AUTOSAR XML (schema 00049)
package /SwComponentTypes
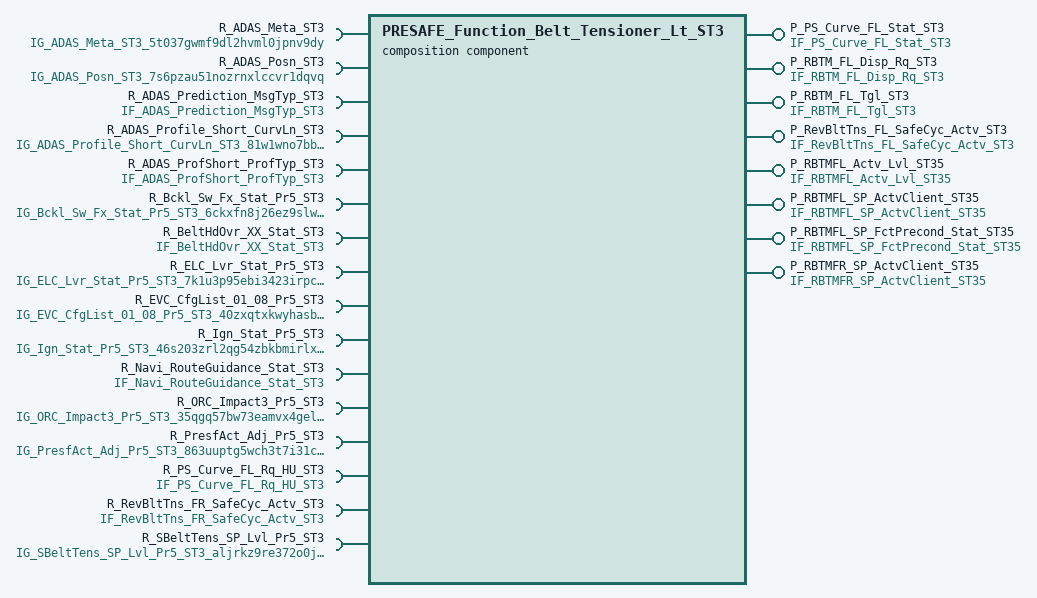
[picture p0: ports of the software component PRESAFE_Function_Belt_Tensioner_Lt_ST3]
  composition sw component type PRESAFE_Function_Belt_Tensioner_Lt_ST3  # Ausführung der reversiblen Gurtsraffung mit Hilfe des Gurtes in Gefahrensituationen / execution of a reversible belt tensioning by belt in critical situations
    4 x provide port:
      P_PS_Curve_FL_Stat_ST3: nonqueued-sender-com-spec{data-element=PS_Curve_FL_Stat_ST3, init-value=constant-reference=XDIS_avyye5ls1y4c08a0jv466vs3h}, provided-interface=IF_PS_Curve_FL_Stat_ST3  # PreSafe Curve Status vorne links / PreSafe Curve mode state front left
      P_RBTM_FL_Disp_Rq_ST3: nonqueued-sender-com-spec{data-element=RBTM_FL_Disp_Rq_ST3, init-value=constant-reference=XDIS_cy54nb3vm043oo6et4rw4sxxi}, provided-interface=IF_RBTM_FL_Disp_Rq_ST3  # Presafe Kombimeldung vorne links anzeigen / Presafe display request front left
      P_RBTM_FL_Tgl_ST3: nonqueued-sender-com-spec{data-element=RBTM_FL_Tgl_ST3, init-value=constant-reference=XDIS_h5tcyk98kzbgrc5svasomeyt}, provided-interface=IF_RBTM_FL_Tgl_ST3  # Presafe Togglebit
      P_RevBltTns_FL_SafeCyc_Actv_ST3: nonqueued-sender-com-spec{data-element=RevBltTns_FL_SafeCyc_Actv_ST3, init-value=constant-reference=XDIS_f4mtuwvd3r353o80f6rps7w7}, provided-interface=IF_RevBltTns_FL_SafeCyc_Actv_ST3  # Reversibler Gurtstraffer vorne links Sicherheits-Straffzyklus aktiv / Reversible belt tensioner front left safety tensioning cycle active
    15 x require port:
      R_ADAS_Meta_ST3: nonqueued-receiver-com-spec{data-element=ADAS_Meta_ST3, reception-props=timeout=10.1, alive-timeout=10.1, init-value=constant-reference=XDIS_e0ppmab9qlp72wzp0n595ikyr}, required-interface=IG_ADAS_Meta_ST3_5t037gwmf9dl2hvml0jpnv9dy  # ADAS Metadaten (degraded) / ADAS meta data (degraded)
      R_ADAS_Posn_ST3: nonqueued-receiver-com-spec{data-element=ADAS_Posn_ST3, reception-props=timeout=5.1, alive-timeout=5.1, init-value=constant-reference=XDIS_12iby7nm3kigcbaip97m7b94m}, required-interface=IG_ADAS_Posn_ST3_7s6pzau51nozrnxlccvr1dqvq  # ADAS Position (degraded)
      R_ADAS_Prediction_MsgTyp_ST3: nonqueued-receiver-com-spec{data-element=ADAS_Prediction_MsgTyp_ST3, reception-props=timeout=0, init-value=constant-reference=XDIS_2a2yz5m526fyufrfge0jdvur9}, required-interface=IF_ADAS_Prediction_MsgTyp_ST3  # ADAS Prediction: Message Type
      R_ADAS_Profile_Short_CurvLn_ST3: nonqueued-receiver-com-spec{data-element=ADAS_Profile_Short_CurvLn_ST3, reception-props=timeout=1.1, alive-timeout=1.1, init-value=constant-reference=XDIS_5q6kecggtt6ixzqit96uyqmo3}, required-interface=IG_ADAS_Profile_Short_CurvLn_ST3_81w1wno7bbxberhwp2jcfr8tz  # ADAS Kurzcharakteristik Curvature Linear (degraded) / ADAS short profile Curvature Linear (degraded)
      R_ADAS_ProfShort_ProfTyp_ST3: nonqueued-receiver-com-spec{data-element=ADAS_ProfShort_ProfTyp_ST3, reception-props=timeout=0, init-value=constant-reference=XDIS_5tr223jg6fys3d0tv4s093nze}, required-interface=IF_ADAS_ProfShort_ProfTyp_ST3  # Profile Short Message: Profiltyp / Profile Short Message: Profile Type
      R_Bckl_Sw_Fx_Stat_Pr5_ST3: nonqueued-receiver-com-spec{data-element=Bckl_Sw_Fx_Stat_Pr5_ST3, reception-props=timeout=0, end-to-end-transformation-com-spec-props{disable-end-to-end-check=false, max-delta-counter=10, max-error-state-init=7, max-error-state-invalid=7, max-error-state-valid=9, min-ok-state-init=3, min-ok-state-invalid=3, min-ok-state-valid=1, window-size-init=10, window-size-invalid=10, window-size-valid=10}, init-value=constant-reference=XDIS_by5k2ulzqy4hav7734lki195k}, required-interface=IG_Bckl_Sw_Fx_Stat_Pr5_ST3_6ckxfn8j26ez9slws8s7zuact  # Bckl Sw Fx Status ST3 (degraded) / Bckl Sw Fx state ST3 (degraded)
      R_BeltHdOvr_XX_Stat_ST3: nonqueued-receiver-com-spec{data-element=BeltHdOvr_XX_Stat_ST3, reception-props=timeout=5.25, alive-timeout=5.25, init-value=constant-reference=XDIS_9pu33xhskzhvc3a6idhpuk7uh}, required-interface=IF_BeltHdOvr_XX_Stat_ST3  # Status Gurtbringer / Belt hand over state
      R_ELC_Lvr_Stat_Pr5_ST3: nonqueued-receiver-com-spec{data-element=ELC_Lvr_Stat_Pr5_ST3, reception-props=timeout=1.1, end-to-end-transformation-com-spec-props=disable-end-to-end-check=true, alive-timeout=1.1, init-value=constant-reference=XDIS_6wuj3k3qgtyyc049tu8amprma}, required-interface=IG_ELC_Lvr_Stat_Pr5_ST3_7k1u3p95ebi3423irpcsvtgpy  # Status Bedienhebel Außenlicht (degraded) / Exterior light lever state (degraded)
      R_EVC_CfgList_01_08_Pr5_ST3: nonqueued-receiver-com-spec{data-element=EVC_CfgList_01_08_Pr5_ST3, reception-props=timeout=2.5, end-to-end-transformation-com-spec-props=disable-end-to-end-check=true, alive-timeout=2.5, init-value=constant-reference=XDIS_7tqm5jy9oba0thvws62i3l28n}, required-interface=IG_EVC_CfgList_01_08_Pr5_ST3_40zxqtxkwyhasb66rr3qexjf2  # EVC Cfg List 01 08 Pr 5 ST3 (degraded)
      R_Ign_Stat_Pr5_ST3: nonqueued-receiver-com-spec{data-element=Ign_Stat_Pr5_ST3, reception-props=timeout=1.05, end-to-end-transformation-com-spec-props{disable-end-to-end-check=false, max-delta-counter=10, max-error-state-init=7, max-error-state-invalid=7, max-error-state-valid=9, min-ok-state-init=3, min-ok-state-invalid=3, min-ok-state-valid=1, window-size-init=10, window-size-invalid=10, window-size-valid=10}, alive-timeout=1.05, init-value=constant-reference=XDIS_8ptnmozvvqneybwnb1dteqblf}, required-interface=IG_Ign_Stat_Pr5_ST3_46s203zrl2qg54zbkbmirlx2b  # Zuendungsstatus (degraded) / Ignition state (degraded)
      R_Navi_RouteGuidance_Stat_ST3: nonqueued-receiver-com-spec{data-element=Navi_RouteGuidance_Stat_ST3, reception-props=timeout=10.1, alive-timeout=10.1, init-value=constant-reference=XDIS_edxyn89atnnz30urbv61ma706}, required-interface=IF_Navi_RouteGuidance_Stat_ST3  # Navigation Status Zielführung / Navigation route guidance state
      R_ORC_Impact3_Pr5_ST3: nonqueued-receiver-com-spec{data-element=ORC_Impact3_Pr5_ST3, reception-props=timeout=0, end-to-end-transformation-com-spec-props{disable-end-to-end-check=false, max-delta-counter=10, max-error-state-init=7, max-error-state-invalid=7, max-error-state-valid=9, min-ok-state-init=3, min-ok-state-invalid=3, min-ok-state-valid=1, window-size-init=10, window-size-invalid=10, window-size-valid=10}, init-value=constant-reference=XDIS_c1pv78wydh7xh2ji5cbkvskd}, required-interface=IG_ORC_Impact3_Pr5_ST3_35qgq57bw73eamvx4gelk7iiv  # ORC Impact 3 ST3 (degraded)
      R_PresfAct_Adj_Pr5_ST3: nonqueued-receiver-com-spec{data-element=PresfAct_Adj_Pr5_ST3, reception-props=timeout=2.1, end-to-end-transformation-com-spec-props{disable-end-to-end-check=false, max-delta-counter=10, max-error-state-init=7, max-error-state-invalid=7, max-error-state-valid=9, min-ok-state-init=3, min-ok-state-invalid=3, min-ok-state-valid=1, window-size-init=10, window-size-invalid=10, window-size-valid=10}, alive-timeout=2.1, init-value=constant-reference=XDIS_1lex2znuqx5p6s5yy1dyffpdg}, required-interface=IG_PresfAct_Adj_Pr5_ST3_863uuptg5wch3t7i31c8crpa2  # Presf Aktor Steuerung ST3 (degraded) / Presf Actuator adjustment ST3 (degraded)
      R_PS_Curve_FL_Rq_HU_ST3: nonqueued-receiver-com-spec{data-element=PS_Curve_FL_Rq_HU_ST3, reception-props=timeout=10.1, alive-timeout=10.1, init-value=constant-reference=XDIS_avyye5ls1y4c08a0jv466vs3h}, required-interface=IF_PS_Curve_FL_Rq_HU_ST3  # Anforderung PreSafe Curve Modus von Headunit vorne links / PreSafe Curve mode request from headunit front left
      R_RevBltTns_FR_SafeCyc_Actv_ST3: nonqueued-receiver-com-spec{data-element=RevBltTns_FR_SafeCyc_Actv_ST3, reception-props=timeout=0, init-value=constant-reference=XDIS_f4mtuwvd3r353o80f6rps7w7}, required-interface=IF_RevBltTns_FR_SafeCyc_Actv_ST3  # Reversibler Gurtstraffer vorne rechts Sicherheits-Straffzyklus aktiv / Reversible belt tensioner front right safety tensioning cycle active
    provide port P_RBTMFL_Actv_Lvl_ST35: nonqueued-sender-com-spec{data-element=RBTMFL_Actv_Lvl_ST35, init-value=constant-reference=XDIS_chxf7btms1nmfvn0rkw64k08e}, provided-interface=IF_RBTMFL_Actv_Lvl_ST35  # aktives Straffprofil vorne links / active seatbelt tensioning profile front left
    provide port P_RBTMFL_SP_ActvClient_ST35: nonqueued-sender-com-spec{data-element=RBTMFL_SP_ActvClient_ST35, init-value=constant-reference=XDIS_ech1daxmjqjqyzrsfliduv3re}, provided-interface=IF_RBTMFL_SP_ActvClient_ST35  # Anforderungsquelle aktive Gurtstraffung vorne links / Active seatbelt tensioning request source front left
    provide port P_RBTMFL_SP_FctPrecond_Stat_ST35: nonqueued-sender-com-spec{data-element=RBTMFL_SP_FctPrecond_Stat_ST35, init-value=constant-reference=XDIS_ax33oucaqs87guek1p0j7vyqa}, provided-interface=IF_RBTMFL_SP_FctPrecond_Stat_ST35  # Nicht erfüllten Funktionsbedingungen für rev. Gurtstraffung vorne links / List of unfulfilled preconditions for rev. seatbelt tensioning front left
    require port R_SBeltTens_SP_Lvl_Pr5_ST3: nonqueued-receiver-com-spec{data-element=SBeltTens_SP_Lvl_Pr5_ST3, reception-props=timeout=2, end-to-end-transformation-com-spec-props{disable-end-to-end-check=false, e-2-e-profile-compatibility-props=E_2_E_PROFILE_COMPATIBILITY_PROPS_true, max-delta-counter=10, max-error-state-init=7, max-error-state-invalid=7, max-error-state-valid=9, min-ok-state-init=3, min-ok-state-invalid=3, min-ok-state-valid=1, window-size-init=10, window-size-invalid=10, window-size-valid=10}, alive-timeout=2, init-value=constant-reference=XDIS_4wiqeqoz18rz4k73xcp12oii1}, required-interface=IG_SBeltTens_SP_Lvl_Pr5_ST3_aljrkz9re372o0jtum2i5lh8w  # Seat Belt Tensioner SP Lvl ST3 (degraded)
    provide port P_RBTMFR_SP_ActvClient_ST35: nonqueued-sender-com-spec{data-element=RBTMFR_SP_ActvClient_ST35, init-value=constant-reference=XDIS_ech1daxmjqjqyzrsfliduv3re}, provided-interface=IF_RBTMFR_SP_ActvClient_ST35  # Active seatbelt tensioning request source front right
    component BeltTensionerFunction: type=BeltTensionerFunction
